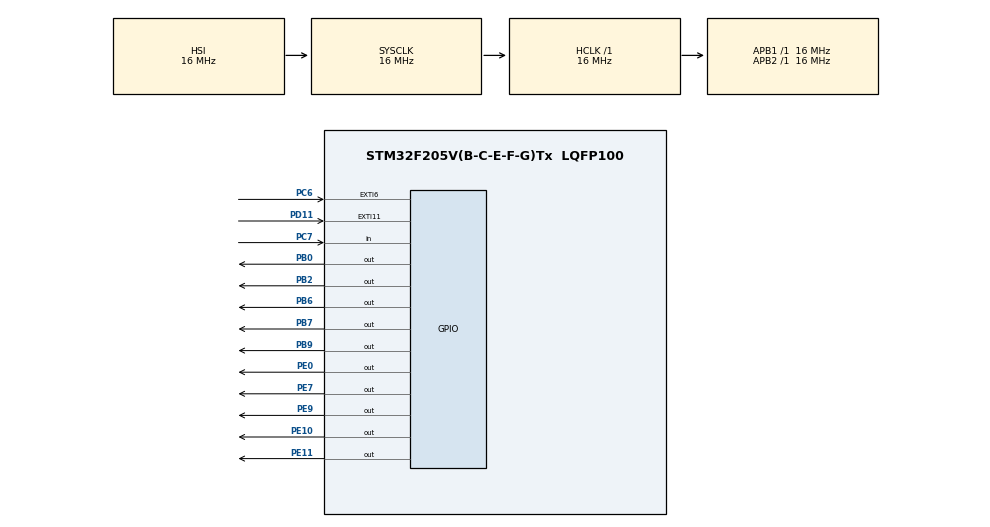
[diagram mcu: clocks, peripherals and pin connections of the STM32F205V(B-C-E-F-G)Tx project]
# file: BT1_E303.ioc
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Mcu.Family=STM32F2
Mcu.Name=STM32F205V(B-C-E-F-G)Tx
Mcu.Package=LQFP100
NVIC.EXTI15_10_IRQn=true\:0\:0\:false\:false\:true\:true\:true\:true
NVIC.EXTI9_5_IRQn=true\:0\:0\:false\:false\:true\:true\:true\:true
NVIC.PriorityGroup=NVIC_PRIORITYGROUP_4
PA13.Mode=Serial_Wire
PA13.Signal=SYS_JTMS-SWDIO
PA14.Mode=Serial_Wire
PA14.Signal=SYS_JTCK-SWCLK
PB0.Signal=GPIO_Output
PB2.Signal=GPIO_Output
PB6.Signal=GPIO_Output
PB7.Signal=GPIO_Output
PB9.Signal=GPIO_Output
PC6.GPIO_PuPd=GPIO_PULLUP
PC6.Signal=GPXTI6
PC7.GPIO_PuPd=GPIO_PULLUP
PC7.Signal=GPIO_Input
PD11.GPIO_ModeDefaultEXTI=GPIO_MODE_IT_FALLING
PD11.GPIO_PuPd=GPIO_PULLUP
PD11.Signal=GPXTI11
PE0.Signal=GPIO_Output
PE10.Signal=GPIO_Output
PE11.Signal=GPIO_Output
PE7.Signal=GPIO_Output
PE9.Signal=GPIO_Output
ProjectManager.HeapSize=0x200
ProjectManager.StackSize=0x400
ProjectManager.TargetToolchain=MDK-ARM V5.32
RCC.48MHZClocksFreq_Value=48000000
RCC.AHBFreq_Value=16000000
RCC.APB1Freq_Value=16000000
RCC.APB2Freq_Value=16000000
RCC.CortexFreq_Value=16000000
RCC.HSE_VALUE=25000000
RCC.HSI_VALUE=16000000
RCC.LSE_VALUE=32768
RCC.SYSCLKFreq_VALUE=16000000
RCC.VCOOutputFreq_Value=192000000
board=custom

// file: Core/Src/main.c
/* USER CODE BEGIN Header */
/**
  ******************************************************************************
  * @file           : main.c
  * @brief          : Main program body
  ******************************************************************************
  * @attention
  *
  * Copyright (c) 2023 STMicroelectronics.
  * All rights reserved.
  *
  * This software is licensed under terms that can be found in the LICENSE file
  * in the root directory of this software component.
  * If no LICENSE file comes with this software, it is provided AS-IS.
  *
  ******************************************************************************
  */
/* USER CODE END Header */
#include "main.h"
#include "LED.h"

/* USER CODE BEGIN Includes */
volatile	uint8_t state = 2;
uint8_t j = 0;
/* USER CODE END Includes */

void SystemClock_Config(void);
static void MX_GPIO_Init(void);

int main(void)
{

  /* MCU Configuration--------------------------------------------------------*/

  /* Reset of all peripherals, Initializes the Flash interface and the Systick. */
  HAL_Init();

  /* Configure the system clock */
  SystemClock_Config();

  /* Initialize all configured peripherals */
  MX_GPIO_Init();
  /* USER CODE BEGIN 2 */
	uint8_t i = 0;

  /* USER CODE END 2 */

  /* Infinite loop */
  while (1)
  {
	/*	if (state == 1)
	  {
		  i++;
		  if (i > 7) {i = 0;}
		  LED7_Number(i);
		  HAL_Delay(1000);
	  }

	  if (state == 2)
	  {
		  if (i > 0) i--;
		  LED7_Number(i);
		  HAL_Delay(1000);
		  if (i == 0) {i = 8;}

	  } */

		if (state == 0)
	  {
//		  i++;
//		  if (i > 7) {i = 0;}
//		  LED7_Number(i);
//		  HAL_Delay(1000);
		GPIOE -> ODR |= GPIO_PIN_7;
		GPIOE -> ODR |= GPIO_PIN_9;
	  }

	  if (state == 1)
	  {
//		  if (i > 0) i--;
//		  LED7_Number(i);
//		  HAL_Delay(1000);
//		  if (i == 0) {i = 8;}
		  GPIOE -> ODR &= ~GPIO_PIN_7;
		  GPIOE -> ODR &= ~GPIO_PIN_9;

	  }

		if (HAL_GPIO_ReadPin(GPIOC, GPIO_PIN_7) == 0)
	  {
		  HAL_Delay(20);
		  if (HAL_GPIO_ReadPin(GPIOC, GPIO_PIN_7) == 0)
		  {
			  GPIOE -> ODR ^= GPIO_PIN_7;
			  GPIOE -> ODR ^= GPIO_PIN_9;
		  }
		  while (HAL_GPIO_ReadPin(GPIOC, GPIO_PIN_7) == 0);

	  }
  }
}

void SystemClock_Config(void)
{
  RCC_OscInitTypeDef RCC_OscInitStruct = {0};
  RCC_ClkInitTypeDef RCC_ClkInitStruct = {0};

  /** Initializes the RCC Oscillators according to the specified parameters
  * in the RCC_OscInitTypeDef structure.
  */
  RCC_OscInitStruct.OscillatorType = RCC_OSCILLATORTYPE_HSI;
  RCC_OscInitStruct.HSIState = RCC_HSI_ON;
  RCC_OscInitStruct.HSICalibrationValue = RCC_HSICALIBRATION_DEFAULT;
  RCC_OscInitStruct.PLL.PLLState = RCC_PLL_NONE;
  if (HAL_RCC_OscConfig(&RCC_OscInitStruct) != HAL_OK)
  {
    Error_Handler();
  }

  /** Initializes the CPU, AHB and APB buses clocks
  */
  RCC_ClkInitStruct.ClockType = RCC_CLOCKTYPE_HCLK|RCC_CLOCKTYPE_SYSCLK
                              |RCC_CLOCKTYPE_PCLK1|RCC_CLOCKTYPE_PCLK2;
  RCC_ClkInitStruct.SYSCLKSource = RCC_SYSCLKSOURCE_HSI;
  RCC_ClkInitStruct.AHBCLKDivider = RCC_SYSCLK_DIV1;
  RCC_ClkInitStruct.APB1CLKDivider = RCC_HCLK_DIV1;
  RCC_ClkInitStruct.APB2CLKDivider = RCC_HCLK_DIV1;

  if (HAL_RCC_ClockConfig(&RCC_ClkInitStruct, FLASH_LATENCY_0) != HAL_OK)
  {
    Error_Handler();
  }
}

static void MX_GPIO_Init(void)
{
  GPIO_InitTypeDef GPIO_InitStruct = {0};

  /* GPIO Ports Clock Enable */
  __HAL_RCC_GPIOB_CLK_ENABLE();
  __HAL_RCC_GPIOE_CLK_ENABLE();
  __HAL_RCC_GPIOD_CLK_ENABLE();
  __HAL_RCC_GPIOC_CLK_ENABLE();
  __HAL_RCC_GPIOA_CLK_ENABLE();

  /*Configure GPIO pin Output Level */
  HAL_GPIO_WritePin(GPIOB, GPIO_PIN_0|GPIO_PIN_2|GPIO_PIN_6|GPIO_PIN_7
                          |GPIO_PIN_9, 1);

  /*Configure GPIO pin Output Level */
  HAL_GPIO_WritePin(GPIOE, GPIO_PIN_7|GPIO_PIN_9|GPIO_PIN_10|GPIO_PIN_11
                          |GPIO_PIN_0, 1);

  /*Configure GPIO pins : PB0 PB2 PB6 PB7
                           PB9 */
  GPIO_InitStruct.Pin = GPIO_PIN_0|GPIO_PIN_2|GPIO_PIN_6|GPIO_PIN_7
                          |GPIO_PIN_9;
  GPIO_InitStruct.Mode = GPIO_MODE_OUTPUT_PP;
  GPIO_InitStruct.Pull = GPIO_NOPULL;
  GPIO_InitStruct.Speed = GPIO_SPEED_FREQ_LOW;
  HAL_GPIO_Init(GPIOB, &GPIO_InitStruct);

  /*Configure GPIO pins : PE7 PE9 PE10 PE11
                           PE0 */
  GPIO_InitStruct.Pin = GPIO_PIN_7|GPIO_PIN_9|GPIO_PIN_10|GPIO_PIN_11
                          |GPIO_PIN_0;
  GPIO_InitStruct.Mode = GPIO_MODE_OUTPUT_PP;
  GPIO_InitStruct.Pull = GPIO_NOPULL;
  GPIO_InitStruct.Speed = GPIO_SPEED_FREQ_LOW;
  HAL_GPIO_Init(GPIOE, &GPIO_InitStruct);

  /*Configure GPIO pin : PD11 */
  GPIO_InitStruct.Pin = GPIO_PIN_11;
  GPIO_InitStruct.Mode = GPIO_MODE_IT_FALLING;
  GPIO_InitStruct.Pull = GPIO_PULLUP;
  HAL_GPIO_Init(GPIOD, &GPIO_InitStruct);

  /*Configure GPIO pin : PC6 */
  GPIO_InitStruct.Pin = GPIO_PIN_6;
  GPIO_InitStruct.Mode = GPIO_MODE_IT_RISING;
  GPIO_InitStruct.Pull = GPIO_PULLUP;
  HAL_GPIO_Init(GPIOC, &GPIO_InitStruct);

  /*Configure GPIO pin : PC7 */
  GPIO_InitStruct.Pin = GPIO_PIN_7;
  GPIO_InitStruct.Mode = GPIO_MODE_INPUT;
  GPIO_InitStruct.Pull = GPIO_PULLUP;
  HAL_GPIO_Init(GPIOC, &GPIO_InitStruct);

  /* EXTI interrupt init*/
  HAL_NVIC_SetPriority(EXTI9_5_IRQn, 0, 0);
  HAL_NVIC_EnableIRQ(EXTI9_5_IRQn);

  HAL_NVIC_SetPriority(EXTI15_10_IRQn, 0, 0);
  HAL_NVIC_EnableIRQ(EXTI15_10_IRQn);

}

/* USER CODE BEGIN 4 */
void HAL_GPIO_EXTI_Callback(uint16_t GPIO_Pin){
	/*if(GPIO_Pin == GPIO_PIN_11){
		state = 1;
		j++;
		if (j > 7) j = 7;
		LED7_Number(j);
	}
	if(GPIO_Pin == GPIO_PIN_6){
		state = 2;
		if (j > 0) j--;
		LED7_Number(j);
		if (j == 0) j = 0;
	} */

	if(GPIO_Pin == GPIO_PIN_11)
		{
			state = 0;
		}

	if(GPIO_Pin == GPIO_PIN_6)
	{

		state = 1;
	}
}
/* USER CODE END 4 */

void Error_Handler(void)
{
  __disable_irq();
  while (1)
  {
  }
}
